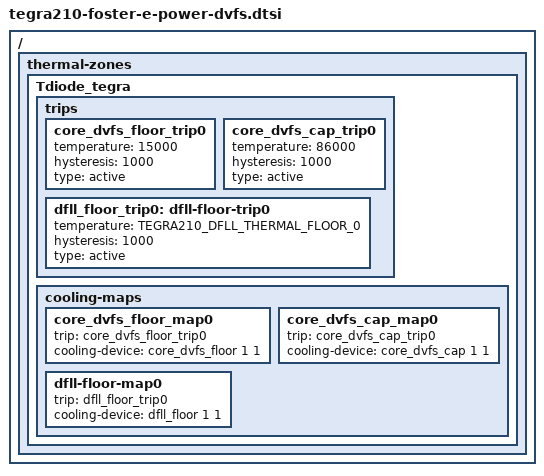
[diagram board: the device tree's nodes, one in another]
/*
 * Copyright (c) 2018, NVIDIA CORPORATION. All rights reserved.
 *
 * This software is licensed under the terms of the GNU General Public
 * License version 2, as published by the Free Software Foundation, and
 * may be copied, distributed, and modified under those terms.
 *
 * This program is distributed in the hope that it will be useful,
 * but WITHOUT ANY WARRANTY; without even the implied warranty of
 * MERCHANTABILITY or FITNESS FOR A PARTICULAR PURPOSE.  See the
 * GNU General Public License for more details.
 *
 */

#include <dt-bindings/thermal/tegra210-trips.h>

/ {
	thermal-zones {
		Tdiode_tegra {
			trips {
				core_dvfs_floor_trip0: core_dvfs_floor_trip0 {
					temperature = <15000>;
					hysteresis = <1000>;
					type = "active";
				};

				core_dvfs_cap_trip0: core_dvfs_cap_trip0 {
					temperature = <86000>;
					hysteresis = <1000>;
					type = "active";
				};

				dfll_floor_trip0: dfll-floor-trip0 {
					temperature = <TEGRA210_DFLL_THERMAL_FLOOR_0>; /* millicelsius */
					hysteresis = <1000>; /* millicelsius */
					type = "active";
				};
			};

			cooling-maps {
				core_dvfs_floor_map0 {
					trip = <&core_dvfs_floor_trip0>;
					cooling-device = <&core_dvfs_floor 1 1>;
				};

				core_dvfs_cap_map0 {
					trip = <&core_dvfs_cap_trip0>;
					cooling-device = <&core_dvfs_cap 1 1>;
				};

				dfll-floor-map0 {
					trip = <&dfll_floor_trip0>;
					cooling-device = <&dfll_floor 1 1>;
				};
			};
		};
	};
};

